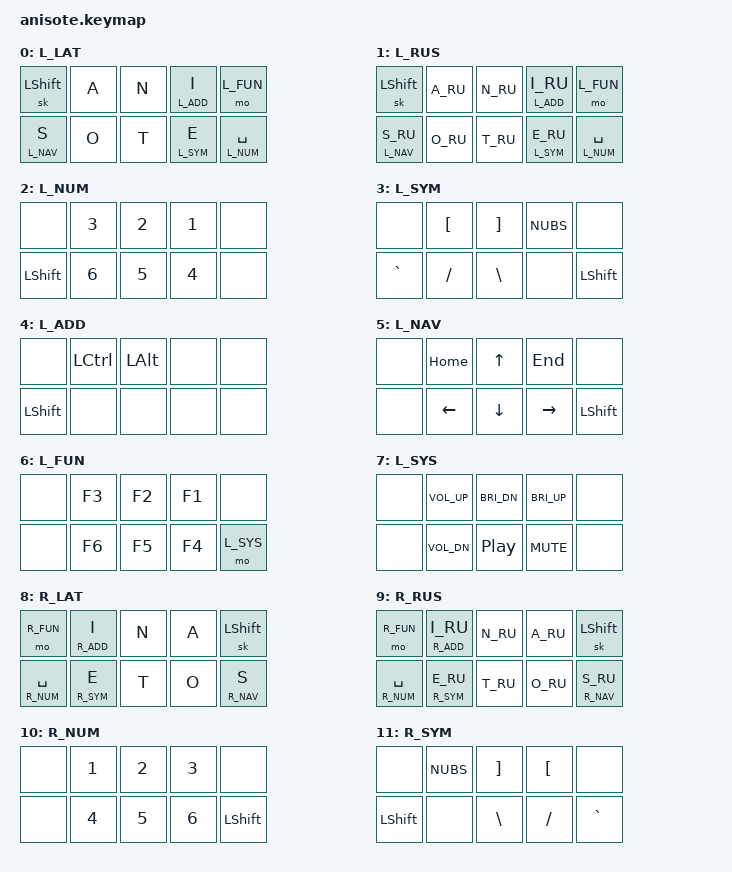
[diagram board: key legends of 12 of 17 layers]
/*
 * Copyright (c) 2021 Mike "KemoNine" Crosson
 *
 * SPDX-License-Identifier: MIT
 */
/*****************************************
 * ARDUX website : https://www.ardux.io
 * Primary reference : https://www.ardux.io/_FILES/images/ARDUX.jpg
*****************************************/

#include <behaviors.dtsi>
#include <dt-bindings/zmk/keys.h>
#include <dt-bindings/zmk/bt.h>
#include <dt-bindings/zmk/outputs.h>
#include <dt-bindings/zmk/mouse.h>

// Timeouts
#define TIMEOUT_LT 300
#define TIMEOUT_TD 300
#define TIMEOUT_SL 1000
#define TIMEOUT_SK 5000
#define TIMEOUT_COMBO 70

#define COMBO_LETTER(BINDINGS, KEYPOS_LEFT, KEYPOS_RIGHT) \
  combo_left_##BINDINGS { \
    bindings      = <&kp BINDINGS>; \
    key-positions = <KEYPOS_LEFT>; \
    layers        = <L_LAT>; \
    timeout-ms    = <TIMEOUT_COMBO>; \
  }; \
  combo_right_##BINDINGS { \
    bindings      = <&kp BINDINGS>; \
    key-positions = <KEYPOS_RIGHT>; \
    layers        = <R_LAT>; \
    timeout-ms    = <TIMEOUT_COMBO>; \
  }; \
  combo_left_##BINDINGS##_ru { \
    bindings      = <&kp BINDINGS ## _RU>; \
    key-positions = <KEYPOS_LEFT>; \
    layers        = <L_RUS>; \
    timeout-ms    = <TIMEOUT_COMBO>; \
  }; \
  combo_right_##BINDINGS##_ru { \
    bindings      = <&kp BINDINGS ## _RU>; \
    key-positions = <KEYPOS_RIGHT>; \
    layers        = <R_RUS>; \
    timeout-ms    = <TIMEOUT_COMBO>; \
  }; 

#define COMBO_KEY(BINDINGS, KEYPOS_LEFT, KEYPOS_RIGHT, LAYER) \
  combo_left_##BINDINGS { \
    bindings      = <&kp BINDINGS>; \
    key-positions = <KEYPOS_LEFT>; \
    layers        = <L_ ## LAYER>; \
    timeout-ms    = <TIMEOUT_COMBO>; \
  }; \
  combo_right_##BINDINGS { \
    bindings      = <&kp BINDINGS>; \
    key-positions = <KEYPOS_RIGHT>; \
    layers        = <R_ ## LAYER>; \
    timeout-ms    = <TIMEOUT_COMBO>; \
  }; 

#define COMBO_SYS(NAME, BINDINGS, KEYPOS_LEFT, KEYPOS_RIGHT, LAYER) \
  combo_left_##NAME { \
    bindings      = <BINDINGS>; \
    key-positions = <KEYPOS_LEFT>; \
    layers        = <L_ ## LAYER>; \
    timeout-ms    = <TIMEOUT_COMBO>; \
  }; \
  combo_right_##NAME { \
    bindings      = <BINDINGS>; \
    key-positions = <KEYPOS_RIGHT>; \
    layers        = <R_ ## LAYER>; \
    timeout-ms    = <TIMEOUT_COMBO>; \
  }; 

#define COMBO(NAME, BINDINGS, KEYPOS, LAYERS) \
  combo_left_##NAME { \
    bindings      = <BINDINGS>; \
    key-positions = <KEYPOS>; \
    layers        = <LAYERS>; \
    timeout-ms    = <TIMEOUT_COMBO>; \
  };

/***************** Keyboard ******************
*    U1 U2 U3 U4 U5      U5R U4R U3R U2R U1R
*    D1 D2 D3 D4 D5      D5R D4R D3R D2R D1R
**********************************************/
#define U1  0
#define U2  1
#define U3  2
#define U4  3
#define U5  4
#define D1  5
#define D2  6
#define D3  7
#define D4  8
#define D5  9

#define U1R  4
#define U2R  3
#define U3R  2
#define U4R  1
#define U5R  0
#define D1R  9
#define D2R  8
#define D3R  7
#define D4R  6
#define D5R  5

#define A_RU F
#define B_RU COMMA
#define C_RU W
#define D_RU L
#define E_RU T
#define F_RU A
#define G_RU U
#define H_RU LBKT
#define I_RU B
#define J_RU Q
#define K_RU R
#define L_RU K
#define M_RU V
#define N_RU Y
#define O_RU J
#define P_RU G
#define Q_RU DOT
#define R_RU H
#define S_RU C
#define T_RU N
#define U_RU E
#define V_RU D
#define W_RU SEMI
#define X_RU Z
#define Y_RU S
#define Z_RU P
#define CH    X
#define CH_RU X
#define SH    I
#define SH_RU I
#define SCH    O
#define SCH_RU O
#define SOFT    M
#define SOFT_RU M
#define HARD    RBKT
#define HARD_RU RBKT
#define YO    GRAVE
#define YO_RU GRAVE
#define AE_RU SQT 

#define COMMA_RU LS(FSLH)
#define DOT_RU      FSLH
#define SEMI_RU  LS(N4)
#define COLON_RU LS(N6)
#define FSLH_RU     KP_DIVIDE
#define QMARK_RU LS(N7)
#define SQT_RU   LA(O)
#define DQT_RU   LS(N2)

#define THUMB &kp SPACE
#define _____ &none

// Layers
#define L_LAT 0
#define L_RUS 1
#define L_LTR 0 1
#define L_NUM 2
#define L_SYM 3
#define L_ADD 4
#define L_NAV 5
#define L_FUN 6
#define L_SYS 7
#define L_ALL 0 1 2 3 4 5 6 7

#define R_LAT 8
#define R_RUS 9
#define R_LTR 8 9
#define R_NUM 10
#define R_SYM 11
#define R_ADD 12
#define R_NAV 13
#define R_FUN 14
#define R_SYS 15
#define R_ALL 9 10 11 12 13 14 15

#define BLE 16

// tune-up default behaviors
&sk { release-after-ms = <TIMEOUT_SK>; quick-release; };
&sl { release-after-ms = <TIMEOUT_SL>; };
&lt { tapping-term-ms  = <TIMEOUT_LT>; flavor = "tap-preferred";} ;

/ {
    combos {
        compatible = "zmk,combos";
        combo_boot { bindings = <&bootloader>; key-positions = < 0 2 4 5 7 9 >; timeout-ms = <TIMEOUT_COMBO>; };
        // combo_repeat        { layers = <L_LTR>; timeout-ms = <T2>; key-positions = <U1 D5>;         bindings = <&key_repeat>; };   rcombo_repeat        { layers = <R_LTR>; timeout-ms = <T2>; key-positions = <U1R D5R>;         bindings = <&key_repeat>; };

// Letters
        // single_a
        COMBO_LETTER( B    , D3 D4 D5    , D3R D4R D5R     )
        COMBO_LETTER( C    , D3 D4       , D3R D4R         )
        COMBO_LETTER( D    , U2 D5       , U2R D5R         )
        // single_e             
        COMBO_LETTER( F    , U3 U4       , U3R U4R         )
        COMBO_LETTER( G    , U2 U3       , U2R U3R         )
        COMBO_LETTER( H    , D4 D5       , D4R D5R         )
        // single_i             
        COMBO_LETTER( J    , D2 D4       , D2R D4R         )
        COMBO_LETTER( K    , U2 U4       , U2R U4R         )
        COMBO_LETTER( L    , U3 D5       , U3R D5R         )
        COMBO_LETTER( M    , D2 D3 D5    , D2R D3R D5R     )
        // single_n             
        // single_o             
        COMBO_LETTER( P    , D2 D4 D5    , D2R D4R D5R     )
        COMBO_LETTER( Q    , U2 U4 D5    , U2R U4R D5R     )
        COMBO_LETTER( R    , D3 D5       , D3R D5R         )
        // single_s             
        // single_t             
        COMBO_LETTER( U    , D2 D3       , D2R D3R         )
        COMBO_LETTER( V    , D1 D5       , D1R D5R         )
        COMBO_LETTER( W    , U4 D5       , U4R D5R         )
        COMBO_LETTER( X    , U2 U3 D5    , U2R U3R D5R     )
        COMBO_LETTER( Y    , D2 D5       , D2R D5R         )
        COMBO_LETTER( Z    , U3 U4 D5    , U3R U4R D5R     )
  
        COMBO_LETTER( CH   , U2 D4       , U2R D4R         )
        COMBO_LETTER( SH   , U3 D2 D4    , U3R D2R D4R     )
        COMBO_LETTER( SCH  , U3 D2 D4 D5 , U3R D2R D4R D5R )
        COMBO_LETTER( SOFT , U2 D3       , U2R D3R         )
        COMBO_LETTER( HARD , U2 D3 D5    , U2R D3R D5R     )
        COMBO_LETTER( YO   , U2 D4 D5    , U2R D4R D5R     )

// Punctuation
        COMBO_LETTER( COMMA, U4 D2       , U4R D2R         )
        COMBO_LETTER( DOT  , U4 D3       , U4R D3R         )
        COMBO_LETTER( SEMI , U4 D2 D5    , U4R D2R D5R     )
        COMBO_LETTER( COLON, U4 D3 D5    , U4R D3R D5R     )
        COMBO_LETTER( FSLH , U4 D1       , U4R D1R         )
        COMBO_LETTER( QMARK, U4 D1 D5    , U4R D1R D5R     )
        COMBO_LETTER( SQT  , U4 D2 D3    , U4R D2R D3R     )
        COMBO_LETTER( DQT  , U4 D2 D3 D5 , U4R D2R D3R D5R )

 // NUM layer 
        COMBO_KEY( N7      , U3 U4       , U3R U4R         , NUM )
        COMBO_KEY( N8      , U2 U3       , U2R U3R         , NUM )
        COMBO_KEY( N9      , D3 D4       , D3R D4R         , NUM )
        COMBO_KEY( N0      , D2 D3       , D2R D3R         , NUM )
        COMBO_KEY( MINUS   , U2 U4       , U2R U4R         , NUM )
        COMBO_KEY( EQUAL   , D2 D4       , D2R D4R         , NUM )
 // FUN layer      
        COMBO_KEY( F7      , U3 U4       , U3R U4R         , FUN )
        COMBO_KEY( F8      , U2 U3       , U2R U3R         , FUN )
        COMBO_KEY( F9      , D3 D4       , D3R D4R         , FUN )
        COMBO_KEY( F10     , D2 D3       , D2R D3R         , FUN )
        COMBO_KEY( F11     , U2 U4       , U2R U4R         , FUN )
        COMBO_KEY( F12     , D2 D4       , D2R D4R         , FUN )

// NAV layer
        COMBO_KEY( PG_UP   , U3 U4       , U3R U4R         , NAV )
        COMBO_KEY( PG_DN   , D3 D4       , D3R D4R         , NAV )
        COMBO_KEY( SPC     , D2 D3 D4    , D2R D3R D4R     , LTR )
        COMBO_KEY( BSPC    , U3 D4       , U3R D4R         , LTR )
        COMBO_KEY( DEL     , U3 D2       , U3R D2R         , LTR )
        COMBO_KEY( TAB     , U2 U3 U4    , U2R U3R U4R     , LTR )
        COMBO_KEY( ESC     , U1 D1       , U1R D1R         , LTR )
        COMBO_KEY( ENTER   , U5 D5       , U5R D5R         , LTR )

// SYS combos
        COMBO_SYS( BSPC_W  , &kp LA(BACKSPACE), U2 U3 D4    , U2R U3R D4R     , LTR )
        COMBO_SYS( DEL_W   , &kp LA(DELETE   ), U3 U4 D2    , U3R U4R D2R     , LTR )
        COMBO_SYS( SHFTLOCK, &kt LSHFT        , U1 D5       , U1R D5R         , LTR )
        COMBO_SYS( LCTRL   , &sk LCTRL        , U2 D2       , U2R D2R         , LTR )
        COMBO_SYS( LALT    , &sk LALT         , U3 D3       , U3R D3R         , LTR )
        COMBO_SYS( LGUI    , &sk LGUI         , U4 D4       , U4R D4R         , LTR )

        COMBO( to_eng_left , &to_eng_l        , D1 D2 D3 D5       , L_LTR R_LTR )
        COMBO( to_rus_left , &to_rus_l        , U1 U2 U3 D5       , L_LTR R_LTR )
        COMBO( to_eng_right, &to_eng_r        , D1R D2R D3R D5R   , L_LTR R_LTR )
        COMBO( to_rus_right, &to_rus_r        , U1R U2R U3R D5R   , L_LTR R_LTR )
 
        COMBO( sl_ble      , &sl BLE          , U1 U5 D1 D5       , L_LTR R_LTR )
        COMBO( clear_ble   , &bt BT_CLR       , U2 U3 D4 D2 D3 D4 , L_LTR R_LTR )

        COMBO( copy_cut    , &td_copy_cut     , D2 D4             , L_NAV R_NAV )
        COMBO( paste       , &kp LG(V)        , U2 U4             , L_NAV R_NAV )
        COMBO( undo        , &kp LG(Z)        , U3 D2 D4          , L_NAV R_NAV )


// 
        // // combo_nav           { layers = <L_NAV>; timeout-ms = <T3>; key-positions = <U3 D2 D4>;       bindings = <&to L_NAV>; };
        // combo_nav_la_esc    { layers = <L_NAV>; timeout-ms = <T2>; key-positions = <U2 U3>;          bindings = <&kp LA(ESC)>; };     rcombo_nav_la_esc    { layers = <R_NAV>; timeout-ms = <T2>; key-positions = <U2R U3R>;          bindings = <&kp LA(ESC)>; };
        // combo_nav_ls_la_esc { layers = <L_NAV>; timeout-ms = <T2>; key-positions = <D2 D3>;          bindings = <&kp LS(LA(ESC))>; }; rcombo_nav_ls_la_esc { layers = <R_NAV>; timeout-ms = <T2>; key-positions = <D2R D3R>;          bindings = <&kp LS(LA(ESC))>; };

        // combo_lock          { layers = <L_ALL>; timeout-ms = <T3>; key-positions = <U2 U4 D3>;       bindings = <&to_eng_lock>; };      rcombo_lock          { layers = <R_ALL>; timeout-ms = <T3>; key-positions = <U2R U4R D3R>;       bindings = <&to_eng_lock_r>; };
        // combo_eject         { layers = <L_ALL>; timeout-ms = <T4>; key-positions = <U4 D1 D2 D3>;    bindings = <&kp C_EJECT>; };       rcombo_eject         { layers = <R_ALL>; timeout-ms = <T4>; key-positions = <U4R D1R D2R D3R>;    bindings = <&kp C_EJECT>; };

    };

    macros {
        to_eng_l: to_eng_l {
            compatible = "zmk,behavior-macro";
            #binding-cells = <0>;
            bindings = <&to L_LAT &kp F18>;};
        to_eng_lock_l: to_eng_lock_l {
            compatible = "zmk,behavior-macro";
            #binding-cells = <0>;
            bindings = <&to L_LAT &kp F18 &kp LC(LG(Q))>;};
        to_rus_l: to_rus_l {
            compatible = "zmk,behavior-macro";
            #binding-cells = <0>;
            bindings = <&to L_RUS &kp F19>;};
        to_eng_r: to_eng_r {
            compatible = "zmk,behavior-macro";
            #binding-cells = <0>;
            bindings = <&to R_LAT &kp F18>;};
        to_eng_lock_r: to_eng_lock_r {
            compatible = "zmk,behavior-macro";
            #binding-cells = <0>;
            bindings = <&to R_LAT &kp F18 &kp LC(LG(Q))>;};
        to_rus_r: to_rus_r {
            compatible = "zmk,behavior-macro";
            #binding-cells = <0>;
            bindings = <&to R_RUS &kp F19>;};
    };

    behaviors {
        td_copy_cut: tap_dance_copy_cut {
            compatible = "zmk,behavior-tap-dance";
            #binding-cells = <0>;
            tapping-term-ms = < TIMEOUT_TD >;
            bindings = <&kp LG(C)>, <&kp LG(X)>;};
    };
};

/ {
    keymap {
        compatible = "zmk,keymap";
        L_LAT {
            bindings = <
                &sk LSHFT           &kp A               &kp N               &lt L_ADD I               &mo L_FUN
                &lt L_NAV S         &kp O               &kp T               &lt L_SYM E               &lt L_NUM SPACE 
            >;
        };
        L_RUS {
            bindings = <
                &sk LSHFT           &kp A_RU            &kp N_RU            &lt L_ADD I_RU            &mo L_FUN
                &lt L_NAV S_RU      &kp O_RU            &kp T_RU            &lt L_SYM E_RU            &lt L_NUM SPACE
            >;
        };
        L_NUM {
            bindings = <
                _____               &kp N3     	        &kp N2              &kp N1                    _____   
                &kp LSHFT           &kp N6              &kp N5              &kp N4                    _____    
            >;
        };
        L_SYM {
           bindings = <
                _____               &kp LBKT            &kp RBKT            &kp NUBS                  _____ 
                &kp GRAVE           &kp FSLH            &kp BSLH            _____                     &kp LSHFT    
            >;
        };
        L_ADD {
            bindings = <
                _____               &kp LCTRL           &kp LALT            _____                     _____   
                &kp LSHFT           &none               &none               &none                     _____    
            >;
        };
        L_NAV {
            bindings = <
                _____               &kp HOME            &kp UP              &kp END                   _____             
                _____               &kp LEFT            &kp DOWN            &kp RIGHT                 &kp LSHFT           
            >;
        };
        L_FUN {
            bindings = <
                _____               &kp F3     	        &kp F2              &kp F1                    _____              
                _____               &kp F6              &kp F5              &kp F4                    &mo L_SYS                
            >;
        };
        L_SYS {
            bindings = <
                _____               &kp C_VOL_UP        &kp C_BRI_DN        &kp C_BRI_UP              _____        
                _____               &kp C_VOL_DN        &kp C_PP            &kp C_MUTE                _____            
            >;
        };

        R_LAT {
            bindings = <
                &mo R_FUN           &lt R_ADD I         &kp N               &kp A                     &sk LSHFT
                &lt R_NUM SPACE     &lt R_SYM E         &kp T               &kp O                     &lt R_NAV S
            >;
        };
        R_RUS {
            bindings = <
                &mo R_FUN           &lt R_ADD I_RU      &kp N_RU            &kp A_RU                  &sk LSHFT
                &lt R_NUM SPACE     &lt R_SYM E_RU      &kp T_RU            &kp O_RU                  &lt R_NAV S_RU
            >;
        };
        R_NUM {
            bindings = <
                _____               &kp N1     	        &kp N2              &kp N3                    _____   
                _____               &kp N4              &kp N5              &kp N6                    &kp LSHFT
            >;
        };
        R_SYM {
           bindings = <
                _____               &kp NUBS            &kp RBKT            &kp LBKT                  _____ 
                &kp LSHFT           _____               &kp BSLH            &kp FSLH                  &kp GRAVE    
            >;
        };
        R_ADD {
            bindings = <
                _____               _____               &kp LALT            &kp LCTRL                 _____   
                _____               &none               &none               &none                     &kp LSHFT    
            >;
        };
        R_NAV {
            bindings = <
                _____               &kp HOME            &kp UP              &kp END                   _____             
                &kp LSHFT           &kp LEFT            &kp DOWN            &kp RIGHT                 _____           
            >;
        };
        R_FUN {
            bindings = <
                _____               &kp F1     	        &kp F2              &kp F3                    _____              
                _____               &kp F4              &kp F5              &kp F6                    &mo R_SYS                 
            >;
        };
        R_SYS {
            bindings = <
                _____               &kp C_BRI_UP        &kp C_BRI_DN        &kp C_VOL_UP              _____        
                _____               &kp C_MUTE          &kp C_PP            &kp C_VOL_DN              _____            
            >;
        };
        BLE {
            bindings = <
                &bt BT_PRV          &bt BT_SEL 0        &bt BT_SEL 1        &bt BT_SEL 2              &bt BT_NXT
                &bt BT_SEL 255      &bt BT_SEL 3        &bt BT_SEL 4        &bt BT_SEL 5              &out OUT_TOG
            >;
        };
    };
};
